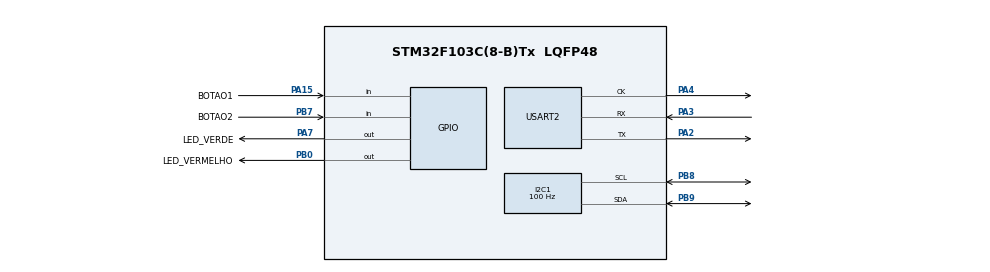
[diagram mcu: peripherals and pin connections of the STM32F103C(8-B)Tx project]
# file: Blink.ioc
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I2C1.ClockSpeed=100
Mcu.Family=STM32F1
Mcu.Name=STM32F103C(8-B)Tx
Mcu.Package=LQFP48
NVIC.PriorityGroup=NVIC_PRIORITYGROUP_4
PA15.GPIO_Label=BOTAO1
PA15.GPIO_Mode=GPIO_MODE_INPUT
PA15.GPIO_PuPd=GPIO_PULLUP
PA15.Signal=GPIO_Input
PA2.Mode=Synchronous
PA2.Signal=USART2_TX
PA3.Mode=Synchronous
PA3.Signal=USART2_RX
PA4.Mode=Synchronous
PA4.Signal=USART2_CK
PA7.GPIO_Label=LED_VERDE
PA7.GPIO_ModeDefaultOutputPP=GPIO_MODE_OUTPUT_PP
PA7.GPIO_PuPd=GPIO_NOPULL
PA7.GPIO_Speed=GPIO_SPEED_FREQ_LOW
PA7.PinState=GPIO_PIN_RESET
PA7.Signal=GPIO_Output
PB0.GPIO_Label=LED_VERMELHO
PB0.GPIO_PuPd=GPIO_NOPULL
PB0.GPIO_Speed=GPIO_SPEED_FREQ_HIGH
PB0.PinState=GPIO_PIN_RESET
PB0.Signal=GPIO_Output
PB7.GPIO_Label=BOTAO2
PB7.GPIO_PuPd=GPIO_PULLDOWN
PB7.Signal=GPIO_Input
PB8.Mode=I2C
PB8.Signal=I2C1_SCL
PB9.Mode=I2C
PB9.Signal=I2C1_SDA
ProjectManager.HeapSize=0x200
ProjectManager.StackSize=0x400
ProjectManager.TargetToolchain=STM32CubeIDE
RCC.APB1Freq_Value=8000000
RCC.APB2Freq_Value=8000000
USART2.VirtualMode=VM_SYNC
VP_SYS_VS_ND.Mode=No_Debug
board=custom

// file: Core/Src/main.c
/* USER CODE BEGIN Header */
/**
  ******************************************************************************
  * @file           : main.c
  * @brief          : Main program body
  ******************************************************************************
  * @attention
  *
  * <h2><center>&copy; Copyright (c) 2020 STMicroelectronics.
  * All rights reserved.</center></h2>
  *
  * This software component is licensed by ST under BSD 3-Clause license,
  * the "License"; You may not use this file except in compliance with the
  * License. You may obtain a copy of the License at:
  *                        opensource.org/licenses/BSD-3-Clause
  *
  ******************************************************************************
  */
/* USER CODE END Header */

#include "main.h"

I2C_HandleTypeDef hi2c1;

USART_HandleTypeDef husart2;

void SystemClock_Config(void);
static void MX_GPIO_Init(void);
static void MX_I2C1_Init(void);
static void MX_USART2_Init(void);

int main(void)
{
  /* USER CODE BEGIN 1 */

	uint8_t buf[12]

  /* USER CODE END 1 */

  /* MCU Configuration--------------------------------------------------------*/

  /* Reset of all peripherals, Initializes the Flash interface and the Systick. */
  HAL_Init();

  /* Configure the system clock */
  SystemClock_Config();

  /* Initialize all configured peripherals */
  MX_GPIO_Init();
  MX_I2C1_Init();
  MX_USART2_Init();

  /* Infinite loop */
  /* USER CODE BEGIN WHILE */
  while (1)
  {
	  HAL_GPIO_WritePin(LED_VERMELHO_GPIO_Port, LED_VERMELHO_Pin, HAL_GPIO_ReadPin(BOTAO1_GPIO_Port, BOTAO1_Pin));
	  HAL_GPIO_WritePin(LED_VERDE_GPIO_Port, LED_VERDE_Pin, HAL_GPIO_ReadPin(BOTAO2_GPIO_Port, BOTAO2_Pin));

    /* USER CODE END WHILE */

  }
}

void SystemClock_Config(void)
{
  RCC_OscInitTypeDef RCC_OscInitStruct = {0};
  RCC_ClkInitTypeDef RCC_ClkInitStruct = {0};

  /** Initializes the CPU, AHB and APB busses clocks
  */
  RCC_OscInitStruct.OscillatorType = RCC_OSCILLATORTYPE_HSI;
  RCC_OscInitStruct.HSIState = RCC_HSI_ON;
  RCC_OscInitStruct.HSICalibrationValue = RCC_HSICALIBRATION_DEFAULT;
  RCC_OscInitStruct.PLL.PLLState = RCC_PLL_NONE;
  if (HAL_RCC_OscConfig(&RCC_OscInitStruct) != HAL_OK)
  {
    Error_Handler();
  }
  /** Initializes the CPU, AHB and APB busses clocks
  */
  RCC_ClkInitStruct.ClockType = RCC_CLOCKTYPE_HCLK|RCC_CLOCKTYPE_SYSCLK
                              |RCC_CLOCKTYPE_PCLK1|RCC_CLOCKTYPE_PCLK2;
  RCC_ClkInitStruct.SYSCLKSource = RCC_SYSCLKSOURCE_HSI;
  RCC_ClkInitStruct.AHBCLKDivider = RCC_SYSCLK_DIV1;
  RCC_ClkInitStruct.APB1CLKDivider = RCC_HCLK_DIV1;
  RCC_ClkInitStruct.APB2CLKDivider = RCC_HCLK_DIV1;

  if (HAL_RCC_ClockConfig(&RCC_ClkInitStruct, FLASH_LATENCY_0) != HAL_OK)
  {
    Error_Handler();
  }
}

static void MX_I2C1_Init(void)
{

  hi2c1.Instance = I2C1;
  hi2c1.Init.ClockSpeed = 100;
  hi2c1.Init.DutyCycle = I2C_DUTYCYCLE_2;
  hi2c1.Init.OwnAddress1 = 0;
  hi2c1.Init.AddressingMode = I2C_ADDRESSINGMODE_7BIT;
  hi2c1.Init.DualAddressMode = I2C_DUALADDRESS_DISABLE;
  hi2c1.Init.OwnAddress2 = 0;
  hi2c1.Init.GeneralCallMode = I2C_GENERALCALL_DISABLE;
  hi2c1.Init.NoStretchMode = I2C_NOSTRETCH_DISABLE;
  if (HAL_I2C_Init(&hi2c1) != HAL_OK)
  {
    Error_Handler();
  }

}

static void MX_USART2_Init(void)
{

  husart2.Instance = USART2;
  husart2.Init.BaudRate = 115200;
  husart2.Init.WordLength = USART_WORDLENGTH_8B;
  husart2.Init.StopBits = USART_STOPBITS_1;
  husart2.Init.Parity = USART_PARITY_NONE;
  husart2.Init.Mode = USART_MODE_TX_RX;
  husart2.Init.CLKPolarity = USART_POLARITY_LOW;
  husart2.Init.CLKPhase = USART_PHASE_1EDGE;
  husart2.Init.CLKLastBit = USART_LASTBIT_DISABLE;
  if (HAL_USART_Init(&husart2) != HAL_OK)
  {
    Error_Handler();
  }

}

static void MX_GPIO_Init(void)
{
  GPIO_InitTypeDef GPIO_InitStruct = {0};

  /* GPIO Ports Clock Enable */
  __HAL_RCC_GPIOA_CLK_ENABLE();
  __HAL_RCC_GPIOB_CLK_ENABLE();

  /*Configure GPIO pin Output Level */
  HAL_GPIO_WritePin(LED_VERDE_GPIO_Port, LED_VERDE_Pin, GPIO_PIN_RESET);

  /*Configure GPIO pin Output Level */
  HAL_GPIO_WritePin(LED_VERMELHO_GPIO_Port, LED_VERMELHO_Pin, GPIO_PIN_RESET);

  /*Configure GPIO pin : LED_VERDE_Pin */
  GPIO_InitStruct.Pin = LED_VERDE_Pin;
  GPIO_InitStruct.Mode = GPIO_MODE_OUTPUT_PP;
  GPIO_InitStruct.Pull = GPIO_NOPULL;
  GPIO_InitStruct.Speed = GPIO_SPEED_FREQ_LOW;
  HAL_GPIO_Init(LED_VERDE_GPIO_Port, &GPIO_InitStruct);

  /*Configure GPIO pin : LED_VERMELHO_Pin */
  GPIO_InitStruct.Pin = LED_VERMELHO_Pin;
  GPIO_InitStruct.Mode = GPIO_MODE_OUTPUT_PP;
  GPIO_InitStruct.Pull = GPIO_NOPULL;
  GPIO_InitStruct.Speed = GPIO_SPEED_FREQ_HIGH;
  HAL_GPIO_Init(LED_VERMELHO_GPIO_Port, &GPIO_InitStruct);

  /*Configure GPIO pin : BOTAO1_Pin */
  GPIO_InitStruct.Pin = BOTAO1_Pin;
  GPIO_InitStruct.Mode = GPIO_MODE_INPUT;
  GPIO_InitStruct.Pull = GPIO_PULLUP;
  HAL_GPIO_Init(BOTAO1_GPIO_Port, &GPIO_InitStruct);

  /*Configure GPIO pin : BOTAO2_Pin */
  GPIO_InitStruct.Pin = BOTAO2_Pin;
  GPIO_InitStruct.Mode = GPIO_MODE_INPUT;
  GPIO_InitStruct.Pull = GPIO_PULLDOWN;
  HAL_GPIO_Init(BOTAO2_GPIO_Port, &GPIO_InitStruct);

}

void Error_Handler(void)
{
}

/************************ (C) COPYRIGHT STMicroelectronics *****END OF FILE****/
